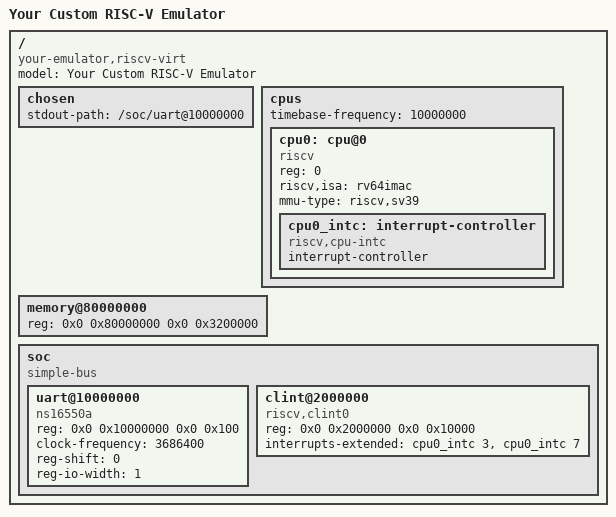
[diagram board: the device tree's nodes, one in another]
/dts-v1/;

/ {
    #address-cells = <2>;
    #size-cells = <2>;
    compatible = "your-emulator,riscv-virt";
    model = "Your Custom RISC-V Emulator";

    chosen {
        /* Tells OpenSBI and Linux to use this UART for terminal output */
        stdout-path = "/soc/uart@10000000";
    };

    cpus {
        #address-cells = <1>;
        #size-cells = <0>;
        timebase-frequency = <10000000>; /* 10 MHz timer frequency */

        cpu0: cpu@0 {
            device_type = "cpu";
            reg = <0>;
            status = "okay";
            compatible = "riscv";
            riscv,isa = "rv64imac"; /* Assuming 64-bit integer, multiply, atomics, compressed */
            mmu-type = "riscv,sv39"; /* Matches your page table walk! */

            cpu0_intc: interrupt-controller {
                #interrupt-cells = <1>;
                interrupt-controller;
                compatible = "riscv,cpu-intc";
            };
        };
    };

    /* RAM configuration */
    memory@80000000 {
        device_type = "memory";
        reg = <0x0 0x80000000 0x0 0x3200000>;
    };

    soc {
        #address-cells = <2>;
        #size-cells = <2>;
        compatible = "simple-bus";
        ranges;

        /* Your Custom UART */
        uart@10000000 {
            /* OpenSBI expects an ns16550a compatible UART by default */
            compatible = "ns16550a";
            reg = <0x0 0x10000000 0x0 0x100>; /* 0x100 bytes of address space */
            clock-frequency = <3686400>;
            reg-shift = <0>;
            reg-io-width = <1>;
        };

        /* CLINT (Core Local Interruptor) for your timer interrupts */
        clint@2000000 {
            compatible = "riscv,clint0";
            /* Standard RISC-V base address for CLINT is usually 0x2000000 */
            reg = <0x0 0x2000000 0x0 0x10000>;
            interrupts-extended = <&cpu0_intc 3 &cpu0_intc 7>; /* M-Soft and M-Timer interrupts */
        };
    };
};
